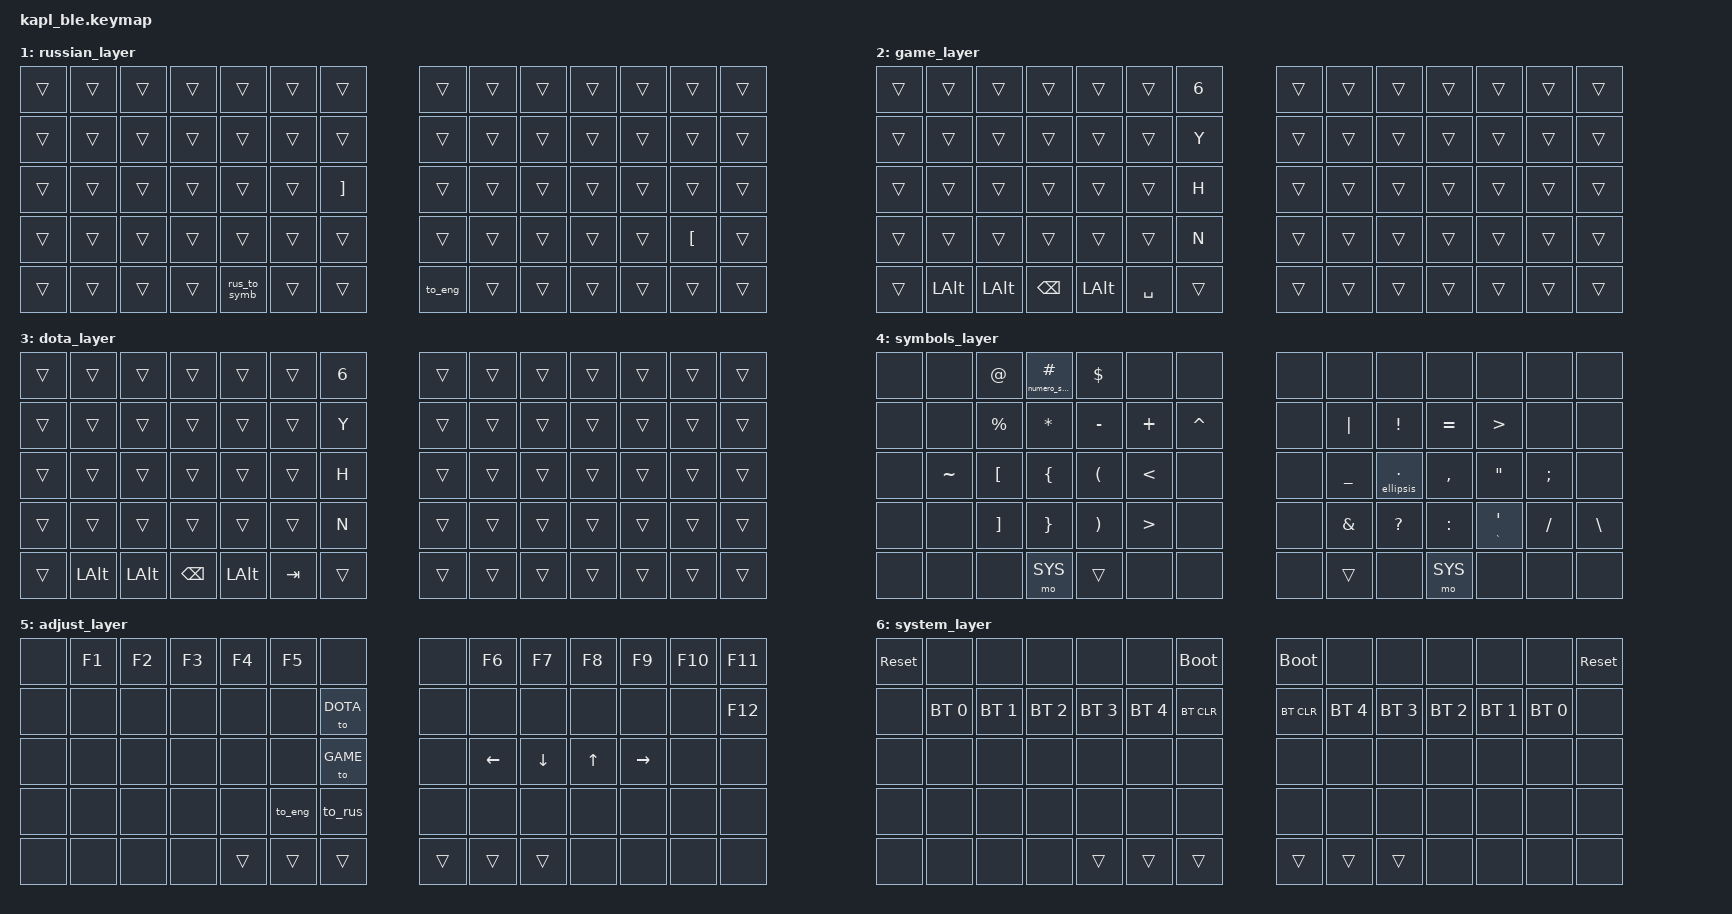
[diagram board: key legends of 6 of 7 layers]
/*
 * Copyright (c) 2021 The ZMK Contributors
 *
 * SPDX-License-Identifier: MIT
 */

#include <behaviors.dtsi>
#include <dt-bindings/zmk/keys.h>
#include <dt-bindings/zmk/bt.h>
#include <dt-bindings/zmk/outputs.h>

#define ENG 0
#define RUS 1
#define GAME 2
#define DOTA 3
#define SYMB 4
#define ADJ 5
#define SYS 6

&lt { quick-tap-ms = <200>; };
&mt { quick-tap-ms = <200>; };

/ {
		combos {
        compatible = "zmk,combos";
				
        combo_plus_minus {
            timeout-ms = <50>;
            key-positions = <18 19>;
            bindings = <&plus_minus>;
						layers = <4>;
        };
				
        combo_en_dash {
            timeout-ms = <50>;
            key-positions = <18 17>;
            bindings = <&en_dash>;
						layers = <4>;
        };
				
        combo_em_dash {
            timeout-ms = <50>;
            key-positions = <18 17 16>;
            bindings = <&em_dash>;
						layers = <4>;
        };
    };

		behaviors {
			ht_numero: ht_numero {
				compatible = "zmk,behavior-hold-tap";
				#binding-cells = <2>;
				flavor = "tap-preferred";
				tapping-term-ms = <200>;
				quick-tap-ms = <200>;
				bindings = <&numero_sign>, <&kp>;
			};
			
			ht_ellipsis: ht_ellipsis {
				compatible = "zmk,behavior-hold-tap";
				#binding-cells = <2>;
				flavor = "tap-preferred";
				tapping-term-ms = <200>;
				quick-tap-ms = <200>;
				bindings = <&ellipsis>, <&kp>;
			};
		};

		macros {
			ZMK_MACRO(
				to_eng,
				bindings
					= <&macro_tap &kp LC(LS(N1))>
					, <&macro_tap &to ENG>
					;
			)
	
			ZMK_MACRO(
				to_rus,
				bindings
					= <&macro_tap &kp LC(LS(N2))>
					, <&macro_tap &to RUS>
					;
			)

			ZMK_MACRO(
				rus_to_symb,
				wait-ms = <10>;
				tap-ms = <25>;
				bindings
					= <&macro_press &mo SYMB>
					, <&macro_tap &kp LC(LS(N1))>
					, <&macro_pause_for_release>
					, <&macro_release &mo SYMB>
					, <&macro_tap_time 25>
					, <&macro_tap &kp LC(LS(N2))>
					;
			)

			ZMK_MACRO(
					plus_minus,
					wait-ms = <10>;
					tap-ms = <25>;
					bindings
							= <&macro_press   &kp LALT>
							, <&macro_tap     &kp KP_N0 &kp KP_N1 &kp KP_N7 &kp KP_N7>
							, <&macro_release &kp LALT>
							;
			)

			ZMK_MACRO(
					ellipsis,
					wait-ms = <10>;
					tap-ms = <25>;
					bindings
							= <&macro_press   &kp LALT>
							, <&macro_tap     &kp KP_N0 &kp KP_N1 &kp KP_N3 &kp KP_N3>
							, <&macro_release &kp LALT>
							;
			)

			ZMK_MACRO(
					en_dash,
					wait-ms = <10>;
					tap-ms = <25>;
					bindings
							= <&macro_press   &kp LALT>
							, <&macro_tap     &kp KP_N0 &kp KP_N1 &kp KP_N5 &kp KP_N0>
							, <&macro_release &kp LALT>
							;
			)

			ZMK_MACRO(
					em_dash,
					wait-ms = <10>;
					tap-ms = <25>;
					bindings
							= <&macro_press   &kp LALT>
							, <&macro_tap     &kp KP_N0 &kp KP_N1 &kp KP_N5 &kp KP_N1>
							, <&macro_release &kp LALT>
							;
			)

			ZMK_MACRO(
					numero_sign,
					wait-ms = <10>;
					tap-ms = <25>;
					bindings
							= <&macro_press   &kp LALT>
							, <&macro_tap     &kp KP_N2 &kp KP_N5 &kp KP_N2>
							, <&macro_release &kp LALT>
							;
			)
		};

				
    keymap {
        compatible =  "zmk,keymap";

				default_layer {
						bindings = <
		&kp ESC     &kp N1     &kp N2    &kp N3    &kp N4   &kp N5    &kp PG_UP             &kp HOME  &kp N6     &kp N7     &kp N8    &kp N9     &kp N0     &kp MINUS
		&kp TAB     &kp Q      &kp W     &kp E     &kp R    &kp T     &kp PG_UP             &kp END   &kp Y      &kp U      &kp I      &kp O     &kp P      &kp EQUAL
		&kp GRAVE   &kp A      &kp S     &kp D     &kp F    &kp G     &kp LBKT              &kp RBKT  &kp H      &kp J      &kp K      &kp L     &kp SEMI   &kp SINGLE_QUOTE
		&kp LSHFT   &kp Z      &kp X     &kp C     &kp V    &kp B     &kp &none             &kp DEL   &kp N      &kp M      &kp COMMA  &kp DOT   &kp SLASH  &kp BSLH
		&kp LCTRL   &kp LWIN   &kp LALT  &kp LALT  &mo SYMB &kp BSPC  &lt ADJ ENTER         &to_rus   &kp SPACE  &none      &kp LEFT  &kp DOWN   &kp UP     &kp RIGHT
						>;

						sensor-bindings = <&inc_dec_kp C_VOL_UP C_VOL_DN>;
				};


				russian_layer {
						bindings = <
		&trans   &trans   &trans   &trans   &trans        &trans   &trans            &trans    &trans   &trans   &trans   &trans   &trans    &trans
		&trans   &trans   &trans   &trans   &trans        &trans   &trans            &trans    &trans   &trans   &trans   &trans   &trans    &trans
		&trans   &trans   &trans   &trans   &trans        &trans   &kp RBKT          &trans    &trans   &trans   &trans   &trans   &trans    &trans
		&trans   &trans   &trans   &trans   &trans        &trans   &trans            &trans    &trans   &trans   &trans   &trans   &kp LBKT  &trans
		&trans   &trans   &trans   &trans   &rus_to_symb  &trans   &trans            &to_eng   &trans   &trans   &trans   &trans   &trans    &trans
						>;
				};


				game_layer {
						bindings = <
		&trans   &trans    &trans     &trans    &trans    &trans     &kp N6            &trans    &trans   &trans   &trans   &trans   &trans    &trans
		&trans   &trans    &trans     &trans    &trans    &trans     &kp Y             &trans    &trans   &trans   &trans   &trans   &trans    &trans
		&trans   &trans    &trans     &trans    &trans    &trans     &kp H             &trans    &trans   &trans   &trans   &trans   &trans    &trans
		&trans   &trans    &trans     &trans    &trans    &trans     &kp N             &trans    &trans   &trans   &trans   &trans   &trans    &trans
		&trans   &kp LALT  &kp LALT   &kp BSPC  &kp LALT  &kp SPACE  &trans            &trans    &trans   &trans   &trans   &trans   &trans    &trans
						>;
				};


				dota_layer {
						bindings = <
		&trans   &trans    &trans     &trans    &trans    &trans   &kp N6           &trans    &trans   &trans   &trans   &trans   &trans    &trans
		&trans   &trans    &trans     &trans    &trans    &trans   &kp Y            &trans    &trans   &trans   &trans   &trans   &trans    &trans
		&trans   &trans    &trans     &trans    &trans    &trans   &kp H            &trans    &trans   &trans   &trans   &trans   &trans    &trans
		&trans   &trans    &trans     &trans    &trans    &trans   &kp N            &trans    &trans   &trans   &trans   &trans   &trans    &trans
		&trans   &kp LALT  &kp LALT   &kp BSPC  &kp LALT  &kp TAB  &trans           &trans    &trans   &trans   &trans   &trans   &trans    &trans
						>;
				};


				symbols_layer {
						bindings = <
		&none   &none       &kp AT_SIGN  &ht_numero 0 HASH   &kp DOLLAR  &none     &none               &none    &none      &none                 &none      &none           &none     &none
		&none   &none       &kp PERCENT  &kp STAR            &kp MINUS   &kp PLUS  &kp CARET           &none    &kp PIPE   &kp EXCL              &kp EQUAL  &kp GT          &none     &none
		&none   &kp TILDE   &kp LBKT     &kp LBRC            &kp LPAR    &kp LT    &none               &none    &kp UNDER  &ht_ellipsis 0 DOT    &kp COMMA  &kp DQT         &kp SEMI  &none
		&none   &none       &kp RBKT     &kp RBRC            &kp RPAR    &kp GT    &none               &none    &kp AMPS   &kp QMARK             &kp COLON  &mt GRAVE APOS  &kp FSLH  &kp BSLH
		&none   &none       &none        &mo SYS             &trans      &none     &none               &none    &trans     &none                 &mo SYS    &none           &none     &none
						>;
				};


				adjust_layer {
						bindings = < 
	&none   &kp F1  &kp F2   &kp F3  &kp F4   &kp F5    &none            &none    &kp F6        &kp F7        &kp F8       &kp F9        &kp F10  &kp F11
	&none   &none   &none    &none   &none    &none     &to DOTA         &none    &none         &none         &none       &none          &none    &kp F12
	&none   &none   &none    &none   &none    &none     &to GAME         &none    &kp LEFT      &kp DOWN      &kp UP      &kp RIGHT      &none    &none
	&none   &none   &none    &none   &none    &to_eng   &to_rus          &none    &none         &none         &none       &none          &none    &none
	&none   &none   &none    &none   &trans   &trans    &trans           &trans   &trans        &trans        &none       &none          &none    &none
						>;
				};


				system_layer {
						bindings = <
	&sys_reset    &none         &none         &none         &none         &none         &bootloader      &bootloader  &none         &none         &none         &none         &none         &sys_reset
	&none         &bt BT_SEL 0  &bt BT_SEL 1  &bt BT_SEL 2  &bt BT_SEL 3  &bt BT_SEL 4  &bt BT_CLR       &bt BT_CLR   &bt BT_SEL 4  &bt BT_SEL 3  &bt BT_SEL 2  &bt BT_SEL 1  &bt BT_SEL 0  &none
	&none         &none         &none         &none         &none         &none         &none            &none        &none         &none         &none         &none         &none         &none
	&none         &none         &none         &none         &none         &none         &none            &none        &none         &none         &none         &none         &none         &none
	&none         &none         &none         &none         &trans        &trans        &trans           &trans       &trans        &trans        &none         &none         &none         &none
					>;
				};

		};
};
